VERSION ""

NS_ :

BS_:

BU_: BMS

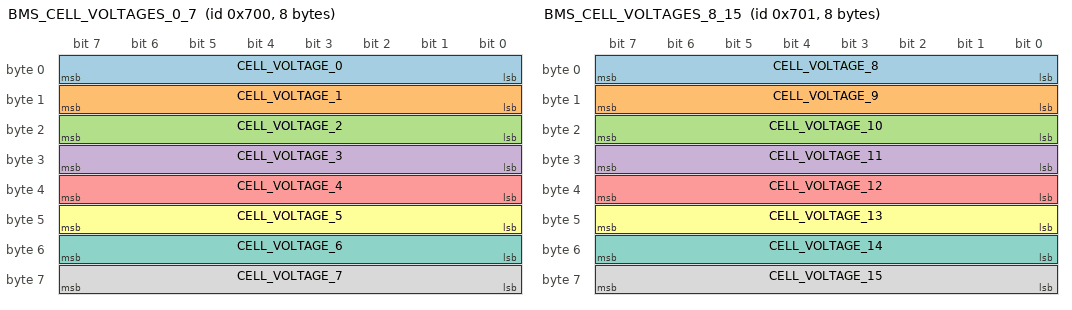
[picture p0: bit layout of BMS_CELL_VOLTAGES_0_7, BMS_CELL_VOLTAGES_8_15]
BO_ 1792 BMS_CELL_VOLTAGES_0_7: 8 BMS
 SG_ CELL_VOLTAGE_0 : 0|8@1+ (0.03125,0) [0|7.96875] "V" Vector__XXX
 SG_ CELL_VOLTAGE_1 : 8|8@1+ (0.03125,0) [0|7.96875] "V" Vector__XXX
 SG_ CELL_VOLTAGE_2 : 16|8@1+ (0.03125,0) [0|7.96875] "V" Vector__XXX
 SG_ CELL_VOLTAGE_3 : 24|8@1+ (0.03125,0) [0|7.96875] "V" Vector__XXX
 SG_ CELL_VOLTAGE_4 : 32|8@1+ (0.03125,0) [0|7.96875] "V" Vector__XXX
 SG_ CELL_VOLTAGE_5 : 40|8@1+ (0.03125,0) [0|7.96875] "V" Vector__XXX
 SG_ CELL_VOLTAGE_6 : 48|8@1+ (0.03125,0) [0|7.96875] "V" Vector__XXX
 SG_ CELL_VOLTAGE_7 : 56|8@1+ (0.03125,0) [0|7.96875] "V" Vector__XXX

BO_ 1793 BMS_CELL_VOLTAGES_8_15: 8 BMS
 SG_ CELL_VOLTAGE_8 : 0|8@1+ (0.03125,0) [0|7.96875] "V" Vector__XXX
 SG_ CELL_VOLTAGE_9 : 8|8@1+ (0.03125,0) [0|7.96875] "V" Vector__XXX
 SG_ CELL_VOLTAGE_10 : 16|8@1+ (0.03125,0) [0|7.96875] "V" Vector__XXX
 SG_ CELL_VOLTAGE_11 : 24|8@1+ (0.03125,0) [0|7.96875] "V" Vector__XXX
 SG_ CELL_VOLTAGE_12 : 32|8@1+ (0.03125,0) [0|7.96875] "V" Vector__XXX
 SG_ CELL_VOLTAGE_13 : 40|8@1+ (0.03125,0) [0|7.96875] "V" Vector__XXX
 SG_ CELL_VOLTAGE_14 : 48|8@1+ (0.03125,0) [0|7.96875] "V" Vector__XXX
 SG_ CELL_VOLTAGE_15 : 56|8@1+ (0.03125,0) [0|7.96875] "V" Vector__XXX

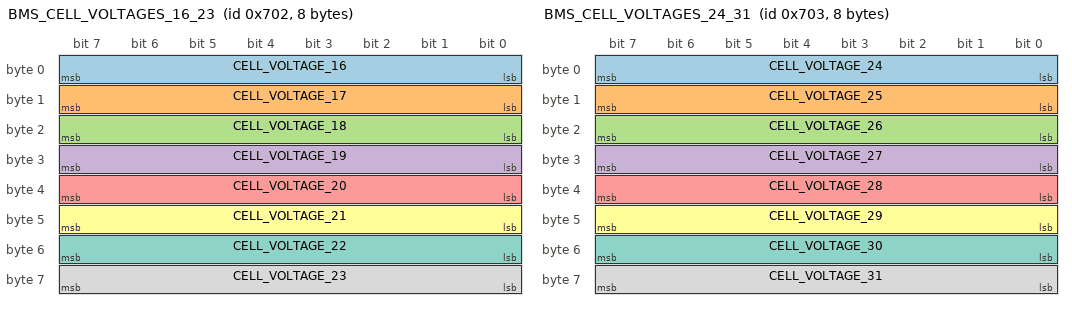
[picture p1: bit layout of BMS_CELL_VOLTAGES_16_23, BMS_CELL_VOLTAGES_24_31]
BO_ 1794 BMS_CELL_VOLTAGES_16_23: 8 BMS
 SG_ CELL_VOLTAGE_16 : 0|8@1+ (0.03125,0) [0|7.96875] "V" Vector__XXX
 SG_ CELL_VOLTAGE_17 : 8|8@1+ (0.03125,0) [0|7.96875] "V" Vector__XXX
 SG_ CELL_VOLTAGE_18 : 16|8@1+ (0.03125,0) [0|7.96875] "V" Vector__XXX
 SG_ CELL_VOLTAGE_19 : 24|8@1+ (0.03125,0) [0|7.96875] "V" Vector__XXX
 SG_ CELL_VOLTAGE_20 : 32|8@1+ (0.03125,0) [0|7.96875] "V" Vector__XXX
 SG_ CELL_VOLTAGE_21 : 40|8@1+ (0.03125,0) [0|7.96875] "V" Vector__XXX
 SG_ CELL_VOLTAGE_22 : 48|8@1+ (0.03125,0) [0|7.96875] "V" Vector__XXX
 SG_ CELL_VOLTAGE_23 : 56|8@1+ (0.03125,0) [0|7.96875] "V" Vector__XXX

BO_ 1795 BMS_CELL_VOLTAGES_24_31: 8 BMS
 SG_ CELL_VOLTAGE_24 : 0|8@1+ (0.03125,0) [0|7.96875] "V" Vector__XXX
 SG_ CELL_VOLTAGE_25 : 8|8@1+ (0.03125,0) [0|7.96875] "V" Vector__XXX
 SG_ CELL_VOLTAGE_26 : 16|8@1+ (0.03125,0) [0|7.96875] "V" Vector__XXX
 SG_ CELL_VOLTAGE_27 : 24|8@1+ (0.03125,0) [0|7.96875] "V" Vector__XXX
 SG_ CELL_VOLTAGE_28 : 32|8@1+ (0.03125,0) [0|7.96875] "V" Vector__XXX
 SG_ CELL_VOLTAGE_29 : 40|8@1+ (0.03125,0) [0|7.96875] "V" Vector__XXX
 SG_ CELL_VOLTAGE_30 : 48|8@1+ (0.03125,0) [0|7.96875] "V" Vector__XXX
 SG_ CELL_VOLTAGE_31 : 56|8@1+ (0.03125,0) [0|7.96875] "V" Vector__XXX

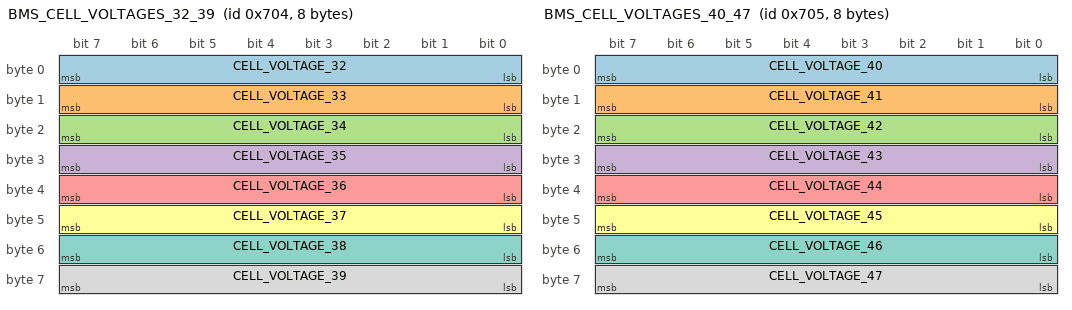
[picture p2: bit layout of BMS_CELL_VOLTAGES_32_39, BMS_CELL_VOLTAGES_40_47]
BO_ 1796 BMS_CELL_VOLTAGES_32_39: 8 BMS
 SG_ CELL_VOLTAGE_32 : 0|8@1+ (0.03125,0) [0|7.96875] "V" Vector__XXX
 SG_ CELL_VOLTAGE_33 : 8|8@1+ (0.03125,0) [0|7.96875] "V" Vector__XXX
 SG_ CELL_VOLTAGE_34 : 16|8@1+ (0.03125,0) [0|7.96875] "V" Vector__XXX
 SG_ CELL_VOLTAGE_35 : 24|8@1+ (0.03125,0) [0|7.96875] "V" Vector__XXX
 SG_ CELL_VOLTAGE_36 : 32|8@1+ (0.03125,0) [0|7.96875] "V" Vector__XXX
 SG_ CELL_VOLTAGE_37 : 40|8@1+ (0.03125,0) [0|7.96875] "V" Vector__XXX
 SG_ CELL_VOLTAGE_38 : 48|8@1+ (0.03125,0) [0|7.96875] "V" Vector__XXX
 SG_ CELL_VOLTAGE_39 : 56|8@1+ (0.03125,0) [0|7.96875] "V" Vector__XXX

BO_ 1797 BMS_CELL_VOLTAGES_40_47: 8 BMS
 SG_ CELL_VOLTAGE_40 : 0|8@1+ (0.03125,0) [0|7.96875] "V" Vector__XXX
 SG_ CELL_VOLTAGE_41 : 8|8@1+ (0.03125,0) [0|7.96875] "V" Vector__XXX
 SG_ CELL_VOLTAGE_42 : 16|8@1+ (0.03125,0) [0|7.96875] "V" Vector__XXX
 SG_ CELL_VOLTAGE_43 : 24|8@1+ (0.03125,0) [0|7.96875] "V" Vector__XXX
 SG_ CELL_VOLTAGE_44 : 32|8@1+ (0.03125,0) [0|7.96875] "V" Vector__XXX
 SG_ CELL_VOLTAGE_45 : 40|8@1+ (0.03125,0) [0|7.96875] "V" Vector__XXX
 SG_ CELL_VOLTAGE_46 : 48|8@1+ (0.03125,0) [0|7.96875] "V" Vector__XXX
 SG_ CELL_VOLTAGE_47 : 56|8@1+ (0.03125,0) [0|7.96875] "V" Vector__XXX

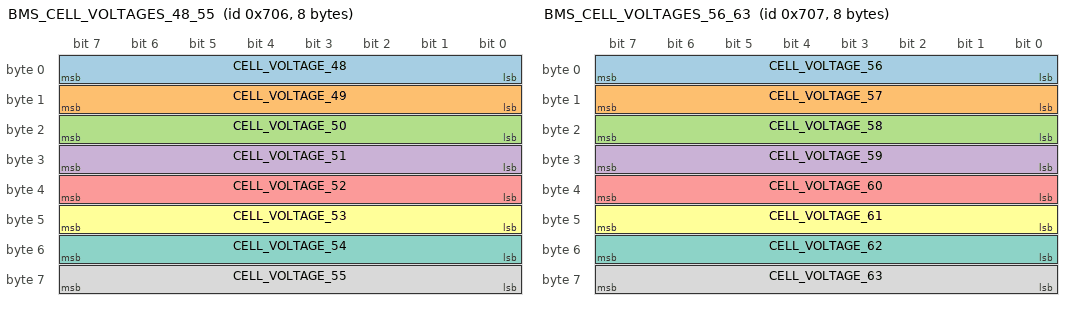
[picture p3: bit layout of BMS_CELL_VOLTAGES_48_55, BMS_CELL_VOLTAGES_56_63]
BO_ 1798 BMS_CELL_VOLTAGES_48_55: 8 BMS
 SG_ CELL_VOLTAGE_48 : 0|8@1+ (0.03125,0) [0|7.96875] "V" Vector__XXX
 SG_ CELL_VOLTAGE_49 : 8|8@1+ (0.03125,0) [0|7.96875] "V" Vector__XXX
 SG_ CELL_VOLTAGE_50 : 16|8@1+ (0.03125,0) [0|7.96875] "V" Vector__XXX
 SG_ CELL_VOLTAGE_51 : 24|8@1+ (0.03125,0) [0|7.96875] "V" Vector__XXX
 SG_ CELL_VOLTAGE_52 : 32|8@1+ (0.03125,0) [0|7.96875] "V" Vector__XXX
 SG_ CELL_VOLTAGE_53 : 40|8@1+ (0.03125,0) [0|7.96875] "V" Vector__XXX
 SG_ CELL_VOLTAGE_54 : 48|8@1+ (0.03125,0) [0|7.96875] "V" Vector__XXX
 SG_ CELL_VOLTAGE_55 : 56|8@1+ (0.03125,0) [0|7.96875] "V" Vector__XXX

BO_ 1799 BMS_CELL_VOLTAGES_56_63: 8 BMS
 SG_ CELL_VOLTAGE_56 : 0|8@1+ (0.03125,0) [0|7.96875] "V" Vector__XXX
 SG_ CELL_VOLTAGE_57 : 8|8@1+ (0.03125,0) [0|7.96875] "V" Vector__XXX
 SG_ CELL_VOLTAGE_58 : 16|8@1+ (0.03125,0) [0|7.96875] "V" Vector__XXX
 SG_ CELL_VOLTAGE_59 : 24|8@1+ (0.03125,0) [0|7.96875] "V" Vector__XXX
 SG_ CELL_VOLTAGE_60 : 32|8@1+ (0.03125,0) [0|7.96875] "V" Vector__XXX
 SG_ CELL_VOLTAGE_61 : 40|8@1+ (0.03125,0) [0|7.96875] "V" Vector__XXX
 SG_ CELL_VOLTAGE_62 : 48|8@1+ (0.03125,0) [0|7.96875] "V" Vector__XXX
 SG_ CELL_VOLTAGE_63 : 56|8@1+ (0.03125,0) [0|7.96875] "V" Vector__XXX

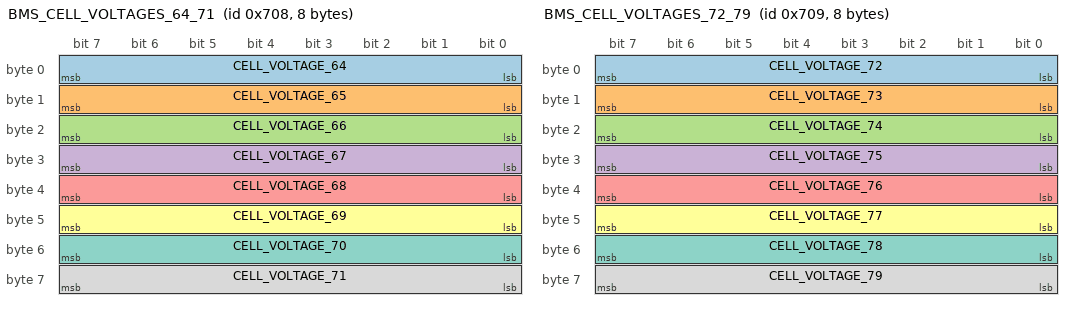
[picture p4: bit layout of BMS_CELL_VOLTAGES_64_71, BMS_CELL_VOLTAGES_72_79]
BO_ 1800 BMS_CELL_VOLTAGES_64_71: 8 BMS
 SG_ CELL_VOLTAGE_64 : 0|8@1+ (0.03125,0) [0|7.96875] "V" Vector__XXX
 SG_ CELL_VOLTAGE_65 : 8|8@1+ (0.03125,0) [0|7.96875] "V" Vector__XXX
 SG_ CELL_VOLTAGE_66 : 16|8@1+ (0.03125,0) [0|7.96875] "V" Vector__XXX
 SG_ CELL_VOLTAGE_67 : 24|8@1+ (0.03125,0) [0|7.96875] "V" Vector__XXX
 SG_ CELL_VOLTAGE_68 : 32|8@1+ (0.03125,0) [0|7.96875] "V" Vector__XXX
 SG_ CELL_VOLTAGE_69 : 40|8@1+ (0.03125,0) [0|7.96875] "V" Vector__XXX
 SG_ CELL_VOLTAGE_70 : 48|8@1+ (0.03125,0) [0|7.96875] "V" Vector__XXX
 SG_ CELL_VOLTAGE_71 : 56|8@1+ (0.03125,0) [0|7.96875] "V" Vector__XXX

BO_ 1801 BMS_CELL_VOLTAGES_72_79: 8 BMS
 SG_ CELL_VOLTAGE_72 : 0|8@1+ (0.03125,0) [0|7.96875] "V" Vector__XXX
 SG_ CELL_VOLTAGE_73 : 8|8@1+ (0.03125,0) [0|7.96875] "V" Vector__XXX
 SG_ CELL_VOLTAGE_74 : 16|8@1+ (0.03125,0) [0|7.96875] "V" Vector__XXX
 SG_ CELL_VOLTAGE_75 : 24|8@1+ (0.03125,0) [0|7.96875] "V" Vector__XXX
 SG_ CELL_VOLTAGE_76 : 32|8@1+ (0.03125,0) [0|7.96875] "V" Vector__XXX
 SG_ CELL_VOLTAGE_77 : 40|8@1+ (0.03125,0) [0|7.96875] "V" Vector__XXX
 SG_ CELL_VOLTAGE_78 : 48|8@1+ (0.03125,0) [0|7.96875] "V" Vector__XXX
 SG_ CELL_VOLTAGE_79 : 56|8@1+ (0.03125,0) [0|7.96875] "V" Vector__XXX

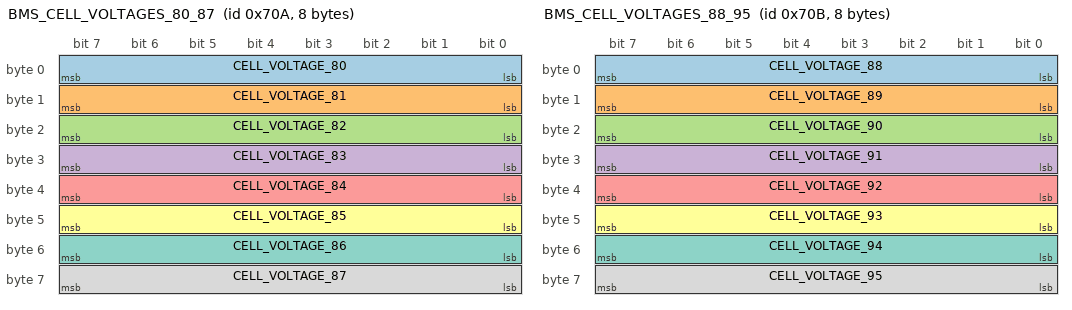
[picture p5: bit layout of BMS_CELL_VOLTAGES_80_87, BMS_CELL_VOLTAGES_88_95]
BO_ 1802 BMS_CELL_VOLTAGES_80_87: 8 BMS
 SG_ CELL_VOLTAGE_80 : 0|8@1+ (0.03125,0) [0|7.96875] "V" Vector__XXX
 SG_ CELL_VOLTAGE_81 : 8|8@1+ (0.03125,0) [0|7.96875] "V" Vector__XXX
 SG_ CELL_VOLTAGE_82 : 16|8@1+ (0.03125,0) [0|7.96875] "V" Vector__XXX
 SG_ CELL_VOLTAGE_83 : 24|8@1+ (0.03125,0) [0|7.96875] "V" Vector__XXX
 SG_ CELL_VOLTAGE_84 : 32|8@1+ (0.03125,0) [0|7.96875] "V" Vector__XXX
 SG_ CELL_VOLTAGE_85 : 40|8@1+ (0.03125,0) [0|7.96875] "V" Vector__XXX
 SG_ CELL_VOLTAGE_86 : 48|8@1+ (0.03125,0) [0|7.96875] "V" Vector__XXX
 SG_ CELL_VOLTAGE_87 : 56|8@1+ (0.03125,0) [0|7.96875] "V" Vector__XXX

BO_ 1803 BMS_CELL_VOLTAGES_88_95: 8 BMS
 SG_ CELL_VOLTAGE_88 : 0|8@1+ (0.03125,0) [0|7.96875] "V" Vector__XXX
 SG_ CELL_VOLTAGE_89 : 8|8@1+ (0.03125,0) [0|7.96875] "V" Vector__XXX
 SG_ CELL_VOLTAGE_90 : 16|8@1+ (0.03125,0) [0|7.96875] "V" Vector__XXX
 SG_ CELL_VOLTAGE_91 : 24|8@1+ (0.03125,0) [0|7.96875] "V" Vector__XXX
 SG_ CELL_VOLTAGE_92 : 32|8@1+ (0.03125,0) [0|7.96875] "V" Vector__XXX
 SG_ CELL_VOLTAGE_93 : 40|8@1+ (0.03125,0) [0|7.96875] "V" Vector__XXX
 SG_ CELL_VOLTAGE_94 : 48|8@1+ (0.03125,0) [0|7.96875] "V" Vector__XXX
 SG_ CELL_VOLTAGE_95 : 56|8@1+ (0.03125,0) [0|7.96875] "V" Vector__XXX

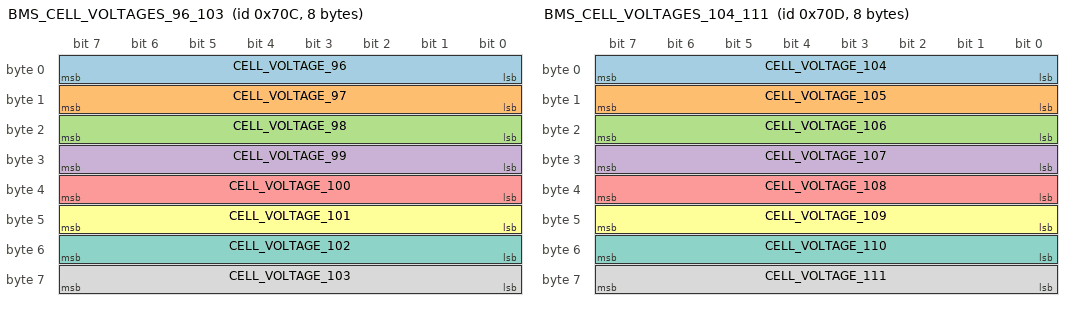
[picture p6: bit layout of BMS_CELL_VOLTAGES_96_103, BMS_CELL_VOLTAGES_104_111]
BO_ 1804 BMS_CELL_VOLTAGES_96_103: 8 BMS
 SG_ CELL_VOLTAGE_96 : 0|8@1+ (0.03125,0) [0|7.96875] "V" Vector__XXX
 SG_ CELL_VOLTAGE_97 : 8|8@1+ (0.03125,0) [0|7.96875] "V" Vector__XXX
 SG_ CELL_VOLTAGE_98 : 16|8@1+ (0.03125,0) [0|7.96875] "V" Vector__XXX
 SG_ CELL_VOLTAGE_99 : 24|8@1+ (0.03125,0) [0|7.96875] "V" Vector__XXX
 SG_ CELL_VOLTAGE_100 : 32|8@1+ (0.03125,0) [0|7.96875] "V" Vector__XXX
 SG_ CELL_VOLTAGE_101 : 40|8@1+ (0.03125,0) [0|7.96875] "V" Vector__XXX
 SG_ CELL_VOLTAGE_102 : 48|8@1+ (0.03125,0) [0|7.96875] "V" Vector__XXX
 SG_ CELL_VOLTAGE_103 : 56|8@1+ (0.03125,0) [0|7.96875] "V" Vector__XXX

BO_ 1805 BMS_CELL_VOLTAGES_104_111: 8 BMS
 SG_ CELL_VOLTAGE_104 : 0|8@1+ (0.03125,0) [0|7.96875] "V" Vector__XXX
 SG_ CELL_VOLTAGE_105 : 8|8@1+ (0.03125,0) [0|7.96875] "V" Vector__XXX
 SG_ CELL_VOLTAGE_106 : 16|8@1+ (0.03125,0) [0|7.96875] "V" Vector__XXX
 SG_ CELL_VOLTAGE_107 : 24|8@1+ (0.03125,0) [0|7.96875] "V" Vector__XXX
 SG_ CELL_VOLTAGE_108 : 32|8@1+ (0.03125,0) [0|7.96875] "V" Vector__XXX
 SG_ CELL_VOLTAGE_109 : 40|8@1+ (0.03125,0) [0|7.96875] "V" Vector__XXX
 SG_ CELL_VOLTAGE_110 : 48|8@1+ (0.03125,0) [0|7.96875] "V" Vector__XXX
 SG_ CELL_VOLTAGE_111 : 56|8@1+ (0.03125,0) [0|7.96875] "V" Vector__XXX

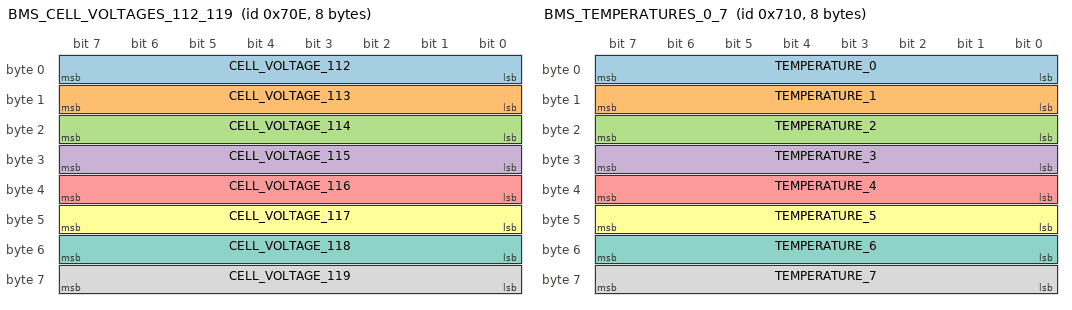
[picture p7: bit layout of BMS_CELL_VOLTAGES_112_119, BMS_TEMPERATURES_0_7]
BO_ 1806 BMS_CELL_VOLTAGES_112_119: 8 BMS
 SG_ CELL_VOLTAGE_112 : 0|8@1+ (0.03125,0) [0|7.96875] "V" Vector__XXX
 SG_ CELL_VOLTAGE_113 : 8|8@1+ (0.03125,0) [0|7.96875] "V" Vector__XXX
 SG_ CELL_VOLTAGE_114 : 16|8@1+ (0.03125,0) [0|7.96875] "V" Vector__XXX
 SG_ CELL_VOLTAGE_115 : 24|8@1+ (0.03125,0) [0|7.96875] "V" Vector__XXX
 SG_ CELL_VOLTAGE_116 : 32|8@1+ (0.03125,0) [0|7.96875] "V" Vector__XXX
 SG_ CELL_VOLTAGE_117 : 40|8@1+ (0.03125,0) [0|7.96875] "V" Vector__XXX
 SG_ CELL_VOLTAGE_118 : 48|8@1+ (0.03125,0) [0|7.96875] "V" Vector__XXX
 SG_ CELL_VOLTAGE_119 : 56|8@1+ (0.03125,0) [0|7.96875] "V" Vector__XXX

BO_ 1808 BMS_TEMPERATURES_0_7: 8 BMS
 SG_ TEMPERATURE_0 : 0|8@1+ (0.5,-28) [-28|99.5] "C" Vector__XXX
 SG_ TEMPERATURE_1 : 8|8@1+ (0.5,-28) [-28|99.5] "C" Vector__XXX
 SG_ TEMPERATURE_2 : 16|8@1+ (0.5,-28) [-28|99.5] "C" Vector__XXX
 SG_ TEMPERATURE_3 : 24|8@1+ (0.5,-28) [-28|99.5] "C" Vector__XXX
 SG_ TEMPERATURE_4 : 32|8@1+ (0.5,-28) [-28|99.5] "C" Vector__XXX
 SG_ TEMPERATURE_5 : 40|8@1+ (0.5,-28) [-28|99.5] "C" Vector__XXX
 SG_ TEMPERATURE_6 : 48|8@1+ (0.5,-28) [-28|99.5] "C" Vector__XXX
 SG_ TEMPERATURE_7 : 56|8@1+ (0.5,-28) [-28|99.5] "C" Vector__XXX

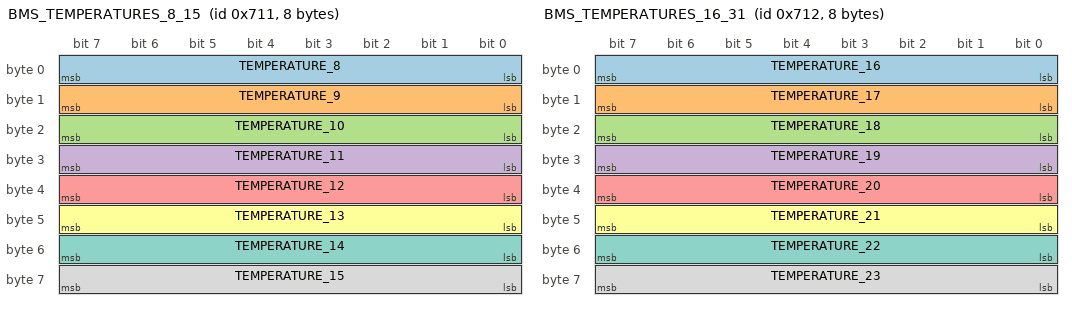
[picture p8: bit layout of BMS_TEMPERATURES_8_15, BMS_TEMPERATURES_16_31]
BO_ 1809 BMS_TEMPERATURES_8_15: 8 BMS
 SG_ TEMPERATURE_8 : 0|8@1+ (0.5,-28) [-28|99.5] "C" Vector__XXX
 SG_ TEMPERATURE_9 : 8|8@1+ (0.5,-28) [-28|99.5] "C" Vector__XXX
 SG_ TEMPERATURE_10 : 16|8@1+ (0.5,-28) [-28|99.5] "C" Vector__XXX
 SG_ TEMPERATURE_11 : 24|8@1+ (0.5,-28) [-28|99.5] "C" Vector__XXX
 SG_ TEMPERATURE_12 : 32|8@1+ (0.5,-28) [-28|99.5] "C" Vector__XXX
 SG_ TEMPERATURE_13 : 40|8@1+ (0.5,-28) [-28|99.5] "C" Vector__XXX
 SG_ TEMPERATURE_14 : 48|8@1+ (0.5,-28) [-28|99.5] "C" Vector__XXX
 SG_ TEMPERATURE_15 : 56|8@1+ (0.5,-28) [-28|99.5] "C" Vector__XXX

BO_ 1810 BMS_TEMPERATURES_16_31: 8 BMS
 SG_ TEMPERATURE_16 : 0|8@1+ (0.5,-28) [-28|99.5] "C" Vector__XXX
 SG_ TEMPERATURE_17 : 8|8@1+ (0.5,-28) [-28|99.5] "C" Vector__XXX
 SG_ TEMPERATURE_18 : 16|8@1+ (0.5,-28) [-28|99.5] "C" Vector__XXX
 SG_ TEMPERATURE_19 : 24|8@1+ (0.5,-28) [-28|99.5] "C" Vector__XXX
 SG_ TEMPERATURE_20 : 32|8@1+ (0.5,-28) [-28|99.5] "C" Vector__XXX
 SG_ TEMPERATURE_21 : 40|8@1+ (0.5,-28) [-28|99.5] "C" Vector__XXX
 SG_ TEMPERATURE_22 : 48|8@1+ (0.5,-28) [-28|99.5] "C" Vector__XXX
 SG_ TEMPERATURE_23 : 56|8@1+ (0.5,-28) [-28|99.5] "C" Vector__XXX

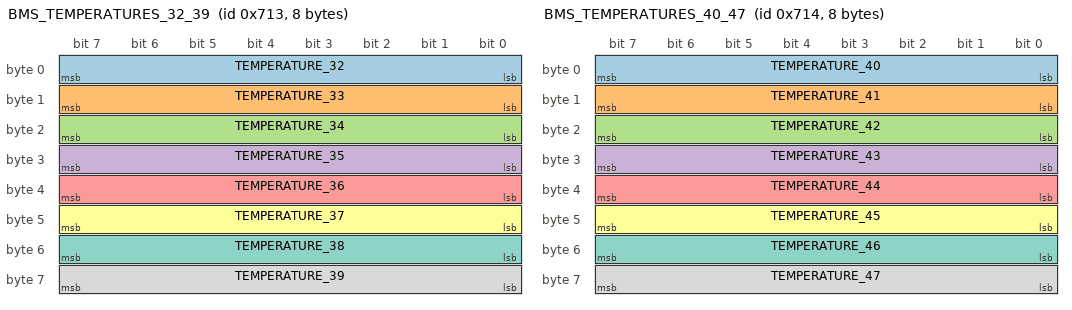
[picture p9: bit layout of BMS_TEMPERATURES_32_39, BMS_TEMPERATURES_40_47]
BO_ 1811 BMS_TEMPERATURES_32_39: 8 BMS
 SG_ TEMPERATURE_32 : 0|8@1+ (0.5,-28) [-28|99.5] "C" Vector__XXX
 SG_ TEMPERATURE_33 : 8|8@1+ (0.5,-28) [-28|99.5] "C" Vector__XXX
 SG_ TEMPERATURE_34 : 16|8@1+ (0.5,-28) [-28|99.5] "C" Vector__XXX
 SG_ TEMPERATURE_35 : 24|8@1+ (0.5,-28) [-28|99.5] "C" Vector__XXX
 SG_ TEMPERATURE_36 : 32|8@1+ (0.5,-28) [-28|99.5] "C" Vector__XXX
 SG_ TEMPERATURE_37 : 40|8@1+ (0.5,-28) [-28|99.5] "C" Vector__XXX
 SG_ TEMPERATURE_38 : 48|8@1+ (0.5,-28) [-28|99.5] "C" Vector__XXX
 SG_ TEMPERATURE_39 : 56|8@1+ (0.5,-28) [-28|99.5] "C" Vector__XXX

BO_ 1812 BMS_TEMPERATURES_40_47: 8 BMS
 SG_ TEMPERATURE_40 : 0|8@1+ (0.5,-28) [-28|99.5] "C" Vector__XXX
 SG_ TEMPERATURE_41 : 8|8@1+ (0.5,-28) [-28|99.5] "C" Vector__XXX
 SG_ TEMPERATURE_42 : 16|8@1+ (0.5,-28) [-28|99.5] "C" Vector__XXX
 SG_ TEMPERATURE_43 : 24|8@1+ (0.5,-28) [-28|99.5] "C" Vector__XXX
 SG_ TEMPERATURE_44 : 32|8@1+ (0.5,-28) [-28|99.5] "C" Vector__XXX
 SG_ TEMPERATURE_45 : 40|8@1+ (0.5,-28) [-28|99.5] "C" Vector__XXX
 SG_ TEMPERATURE_46 : 48|8@1+ (0.5,-28) [-28|99.5] "C" Vector__XXX
 SG_ TEMPERATURE_47 : 56|8@1+ (0.5,-28) [-28|99.5] "C" Vector__XXX

BO_ 1813 BMS_TEMPERATURES_48_49: 8 BMS
 SG_ TEMPERATURE_48 : 0|8@1+ (0.5,-28) [-28|99.5] "C" Vector__XXX
 SG_ TEMPERATURE_49 : 8|8@1+ (0.5,-28) [-28|99.5] "C" Vector__XXX

BA_DEF_  "BusType" STRING ;
BA_DEF_DEF_  "BusType" "CAN";
